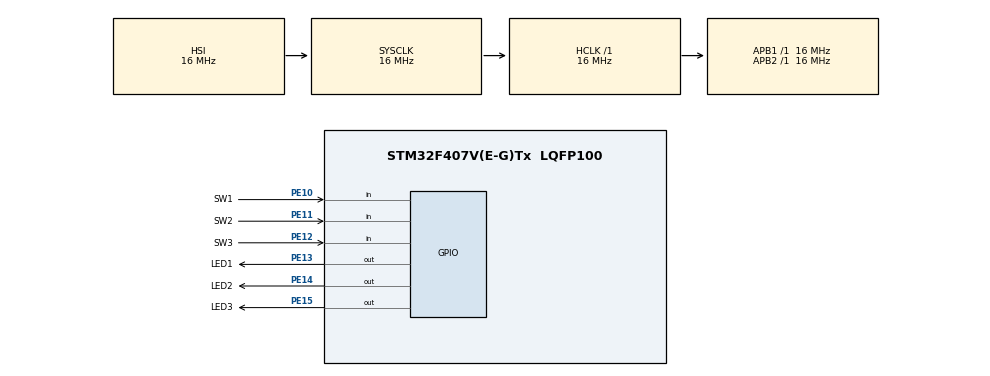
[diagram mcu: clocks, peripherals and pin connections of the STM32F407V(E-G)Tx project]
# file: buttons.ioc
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Mcu.Family=STM32F4
Mcu.Name=STM32F407V(E-G)Tx
Mcu.Package=LQFP100
NVIC.PriorityGroup=NVIC_PRIORITYGROUP_4
PE10.GPIO_Label=SW1
PE10.GPIO_PuPd=GPIO_PULLUP
PE10.Signal=GPIO_Input
PE11.GPIO_Label=SW2
PE11.GPIO_PuPd=GPIO_PULLUP
PE11.Signal=GPIO_Input
PE12.GPIO_Label=SW3
PE12.GPIO_PuPd=GPIO_PULLUP
PE12.Signal=GPIO_Input
PE13.GPIO_Label=LED1
PE13.GPIO_ModeDefaultOutputPP=GPIO_MODE_OUTPUT_PP
PE13.GPIO_PuPd=GPIO_PULLUP
PE13.PinState=GPIO_PIN_SET
PE13.Signal=GPIO_Output
PE14.GPIO_Label=LED2
PE14.GPIO_ModeDefaultOutputPP=GPIO_MODE_OUTPUT_PP
PE14.GPIO_PuPd=GPIO_PULLUP
PE14.PinState=GPIO_PIN_SET
PE14.Signal=GPIO_Output
PE15.GPIO_Label=LED3
PE15.GPIO_ModeDefaultOutputPP=GPIO_MODE_OUTPUT_PP
PE15.GPIO_PuPd=GPIO_PULLUP
PE15.PinState=GPIO_PIN_SET
PE15.Signal=GPIO_Output
ProjectManager.HeapSize=0x200
ProjectManager.StackSize=0x400
ProjectManager.TargetToolchain=STM32CubeIDE
RCC.AHBFreq_Value=16000000
RCC.APB1Freq_Value=16000000
RCC.APB2Freq_Value=16000000
RCC.CortexFreq_Value=16000000
RCC.HSE_VALUE=25000000
RCC.HSI_VALUE=16000000
RCC.LSE_VALUE=32768
RCC.SYSCLKFreq_VALUE=16000000
RCC.VCOOutputFreq_Value=192000000
board=custom

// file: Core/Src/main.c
/* USER CODE BEGIN Header */
/**
  ******************************************************************************
  * @file           : main.c
  * @brief          : Main program body
  ******************************************************************************
  * @attention
  *
  * Copyright (c) 2026 STMicroelectronics.
  * All rights reserved.
  *
  * This software is licensed under terms that can be found in the LICENSE file
  * in the root directory of this software component.
  * If no LICENSE file comes with this software, it is provided AS-IS.
  *
  ******************************************************************************
  */
/* USER CODE END Header */
#include "main.h"
#include "gpio.h"

void SystemClock_Config(void);

int main(void)
{

  /* MCU Configuration--------------------------------------------------------*/

  /* Reset of all peripherals, Initializes the Flash interface and the Systick. */
  HAL_Init();

  /* Configure the system clock */
  SystemClock_Config();

  /* Initialize all configured peripherals */
  MX_GPIO_Init();

  /* Infinite loop */
  /* USER CODE BEGIN WHILE */
  while (1)
  {
	  if (HAL_GPIO_ReadPin(SW1_GPIO_Port, SW1_Pin) == GPIO_PIN_RESET)
	  {
		  HAL_GPIO_WritePin(LED1_GPIO_Port, LED1_Pin, GPIO_PIN_RESET);
	  }
	  else
	  {
		  HAL_GPIO_WritePin(LED1_GPIO_Port, LED1_Pin, GPIO_PIN_SET);
	  }
	  if (HAL_GPIO_ReadPin(SW2_GPIO_Port, SW2_Pin) == GPIO_PIN_RESET)
	  {
		  HAL_GPIO_WritePin(LED2_GPIO_Port, LED2_Pin, GPIO_PIN_RESET);
	  }
	  else
	  {
		  HAL_GPIO_WritePin(LED2_GPIO_Port, LED2_Pin, GPIO_PIN_SET);
	  }
	  if (HAL_GPIO_ReadPin(SW3_GPIO_Port, SW3_Pin) == GPIO_PIN_RESET)
	  {
		  HAL_GPIO_WritePin(LED3_GPIO_Port, LED3_Pin, GPIO_PIN_RESET);
	  }
	  else
	  {
		  HAL_GPIO_WritePin(LED3_GPIO_Port, LED3_Pin, GPIO_PIN_SET);
	  }
    /* USER CODE END WHILE */

  }
}

void SystemClock_Config(void)
{
  RCC_OscInitTypeDef RCC_OscInitStruct = {0};
  RCC_ClkInitTypeDef RCC_ClkInitStruct = {0};

  /** Configure the main internal regulator output voltage
  */
  __HAL_RCC_PWR_CLK_ENABLE();
  __HAL_PWR_VOLTAGESCALING_CONFIG(PWR_REGULATOR_VOLTAGE_SCALE1);

  /** Initializes the RCC Oscillators according to the specified parameters
  * in the RCC_OscInitTypeDef structure.
  */
  RCC_OscInitStruct.OscillatorType = RCC_OSCILLATORTYPE_HSI;
  RCC_OscInitStruct.HSIState = RCC_HSI_ON;
  RCC_OscInitStruct.HSICalibrationValue = RCC_HSICALIBRATION_DEFAULT;
  RCC_OscInitStruct.PLL.PLLState = RCC_PLL_NONE;
  if (HAL_RCC_OscConfig(&RCC_OscInitStruct) != HAL_OK)
  {
    Error_Handler();
  }

  /** Initializes the CPU, AHB and APB buses clocks
  */
  RCC_ClkInitStruct.ClockType = RCC_CLOCKTYPE_HCLK|RCC_CLOCKTYPE_SYSCLK
                              |RCC_CLOCKTYPE_PCLK1|RCC_CLOCKTYPE_PCLK2;
  RCC_ClkInitStruct.SYSCLKSource = RCC_SYSCLKSOURCE_HSI;
  RCC_ClkInitStruct.AHBCLKDivider = RCC_SYSCLK_DIV1;
  RCC_ClkInitStruct.APB1CLKDivider = RCC_HCLK_DIV1;
  RCC_ClkInitStruct.APB2CLKDivider = RCC_HCLK_DIV1;

  if (HAL_RCC_ClockConfig(&RCC_ClkInitStruct, FLASH_LATENCY_0) != HAL_OK)
  {
    Error_Handler();
  }
}

void Error_Handler(void)
{
  __disable_irq();
  while (1)
  {
  }
}
